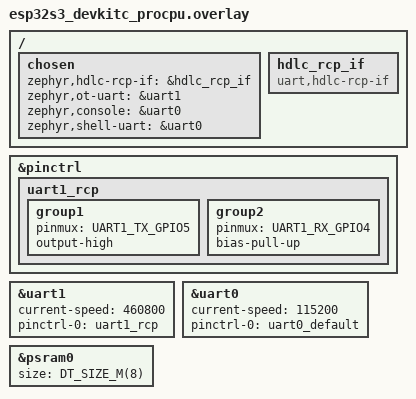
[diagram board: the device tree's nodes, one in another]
/* Spinel link to the ESP32-C6 RCP, crossed: S3 GPIO5 (TX) -> C6 GPIO4 (RX),
 * S3 GPIO4 (RX) <- C6 GPIO5 (TX), plus GND.
 */
/ {
	chosen {
		zephyr,hdlc-rcp-if = &hdlc_rcp_if;
		zephyr,ot-uart = &uart1;
		/* The user shell/console goes through the board's CH343 UART0. */
		zephyr,console = &uart0;
		zephyr,shell-uart = &uart0;
	};

	hdlc_rcp_if: hdlc_rcp_if {
		compatible = "uart,hdlc-rcp-if";
	};
};

&pinctrl {
	uart1_rcp: uart1_rcp {
		group1 {
			pinmux = <UART1_TX_GPIO5>;
			output-high;
		};

		group2 {
			pinmux = <UART1_RX_GPIO4>;
			bias-pull-up;
		};
	};
};

&uart1 {
	status = "okay";
	current-speed = <460800>;
	pinctrl-0 = <&uart1_rcp>;
	pinctrl-names = "default";
};

/* UART0 is routed by the ESP32-S3-DevKitC to CH343 (GPIO43 TX/GPIO44 RX). */
&uart0 {
	status = "okay";
	current-speed = <115200>;
	/delete-property/ hw-flow-control;
	pinctrl-0 = <&uart0_default>;
	pinctrl-names = "default";
};

&psram0 {
	size = <DT_SIZE_M(8)>;
};
